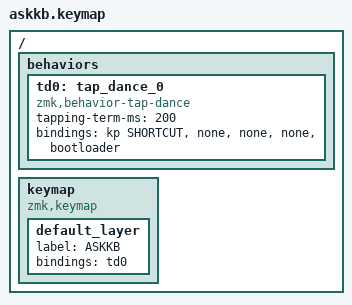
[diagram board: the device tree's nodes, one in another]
/*
*
* Copyright (c) 2024 Rafael Romão
* SPDX-License-Identifier: MIT
*
*/

#include <behaviors.dtsi>
#include <dt-bindings/zmk/keys.h>
#include <dt-bindings/zmk/bt.h>

#define SHORTCUT LC(L)

/ {
        behaviors {
                td0: tap_dance_0 {
                    compatible = "zmk,behavior-tap-dance";
                    #binding-cells = <0>;
                    tapping-term-ms = <200>;
                    bindings = <&kp SHORTCUT>, <&none>, <&none>, <&none>, <&bootloader>;
                };
            };

        keymap {
                compatible = "zmk,keymap";
                default_layer {
                     label = "ASKKB";
                     bindings = <
                        &td0
                        >;
                };
        };
};
